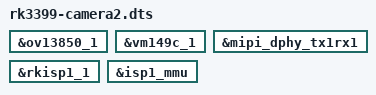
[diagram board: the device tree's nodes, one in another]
/dts-v1/;
/plugin/;

/ {
	fragment@0 {
		target = <&ov13850_1>;
		__overlay__ {
			status = "okay";
		};
	};

	fragment@1 {
		target = <&vm149c_1>;
		__overlay__ {
			status = "okay";
		};
	};

	fragment@2 {
		target = <&mipi_dphy_tx1rx1>;
		__overlay__ {
			status = "okay";
		};
	};

	fragment@3 {
		target = <&rkisp1_1>;
		__overlay__ {
			status = "okay";
		};
	};

	fragment@4 {
		target = <&isp1_mmu>;
		__overlay__ {
			status = "okay";
		};
	};
};
